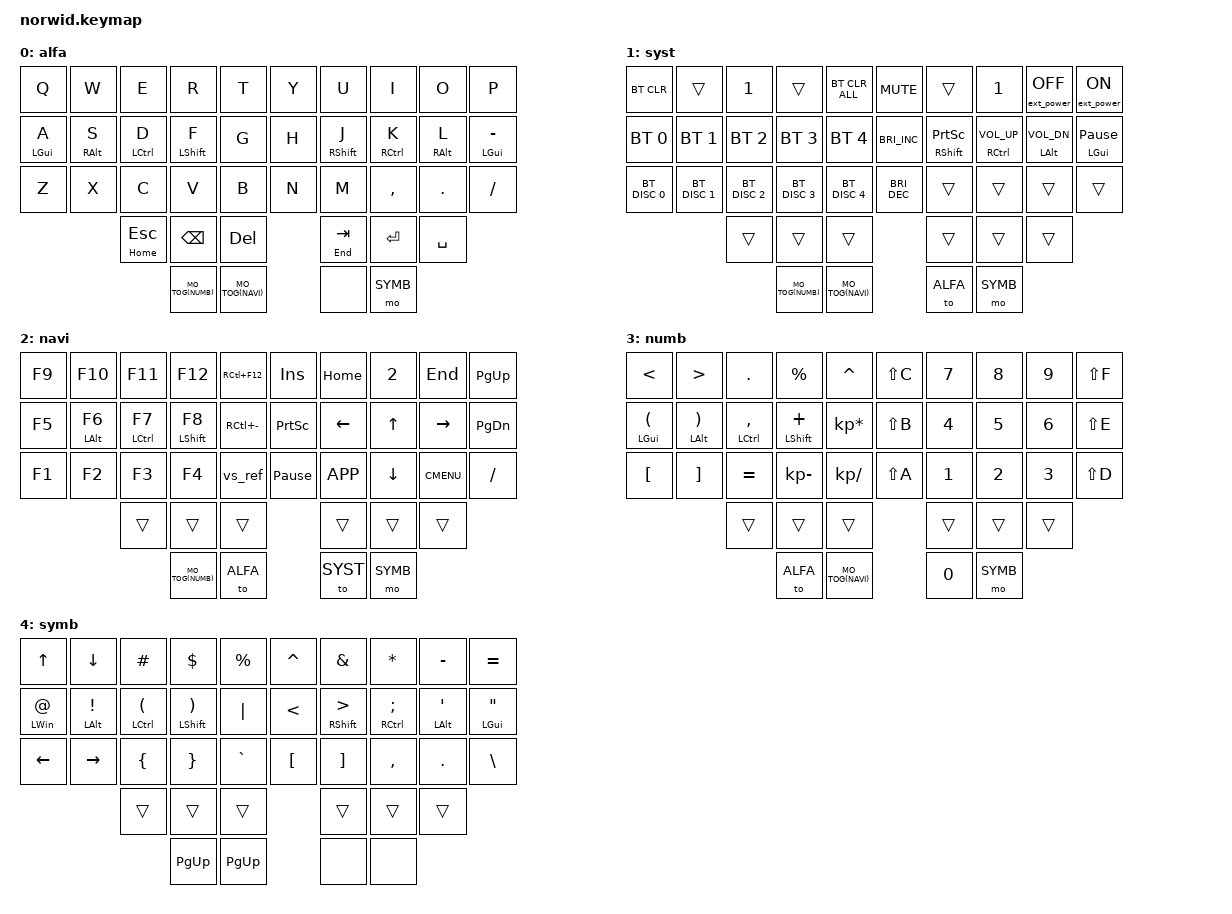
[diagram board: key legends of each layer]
#include <behaviors.dtsi>
#include <dt-bindings/zmk/keys.h>
#include <dt-bindings/zmk/bt.h>
#include <dt-bindings/zmk/outputs.h>
#include <dt-bindings/zmk/ext_power.h>

#define MO_TOG(layer) &mo_tog layer layer 
#define ALFA 0
#define SYST 1
#define NAVI 2
#define NUMB 3
#define SYMB 4


/ {
    macros {
        vs_ref: vs_ref {
            compatible = "zmk,behavior-macro";
            #binding-cells = <0>;
            bindings
                = <&macro_press &kp LCTRL>
                , <&macro_tap &kp K &kp R>
                , <&macro_release &kp LCTRL>
                ;
        };
    };
    behaviors {
        hm: homerow_mods {
            compatible = "zmk,behavior-hold-tap";
            #binding-cells = <2>;
            tapping-term-ms = <250>;
            flavor = "tap-preferred";
            bindings = <&kp>, <&kp>;
        };
        mo_tog: behavior_mo_tog {
            compatible = "zmk,behavior-hold-tap";
            #binding-cells = <2>;
            flavor = "hold-preferred";
            tapping-term-ms = <200>;
            bindings = <&mo>, <&tog>;
        };
        hml: home_row_mod_left {
            compatible = "zmk,behavior-hold-tap";
            display-name = "Home Row Mod L";
            #binding-cells = <2>;
            flavor = "balanced";
            require-prior-idle-ms = <100>;
            tapping-term-ms = <280>;
            quick-tap-ms = <175>;
            bindings = <&kp>, <&kp>;
            hold-trigger-key-positions = <5 6 7 8 9 15 16 17 18 19 25 26 27 28 29 35 36 37 38 39>;
            hold-trigger-on-release;
        };
        hmr: home_row_mod_right {
            compatible = "zmk,behavior-hold-tap";
            display-name = "Home Row Mod R";
            #binding-cells = <2>;
            flavor = "balanced";
            require-prior-idle-ms = <100>;
            tapping-term-ms = <280>;
            quick-tap-ms = <175>;
            bindings = <&kp>, <&kp>;
            hold-trigger-key-positions = <0 1 2 3 4 10 11 12 13 14 20 21 22 23 24 30 31 32 33 34>;
            hold-trigger-on-release;
        };
    };
    keymap {
        compatible = "zmk,keymap";
        alfa_layer {
            display-name = "alfa";
            bindings = <
                &kp Q       &kp W       &kp E        &kp R         &kp T       &kp Y  &kp U        &kp I        &kp O       &kp P
                &hml LGUI A &hml RALT S &hml LCTRL D &hml LSHFT F  &kp G       &kp H  &hmr RSHFT J &hmr RCTRL K &hmr RALT L &hmr LGUI MINUS
                &kp Z       &kp X       &kp C        &kp V         &kp B       &kp N  &kp M        &kp COMMA    &kp DOT     &kp FSLH     
                                        &hml HOME ESC  &kp BSPC    &kp DEL      &hmr END TAB &kp ENTER  &kp SPACE
                                                MO_TOG(NUMB)    MO_TOG(NAVI)           &none   &mo SYMB
            >;
        };
        sys_layer {
            display-name = "syst";
            bindings = <
                &bt BT_CLR    &trans        &kp N1        &trans        &bt BT_CLR_ALL          &kp C_MUTE  &trans      &kp N1      &ext_power EP_OFF      &ext_power EP_ON
                &bt BT_SEL 0  &bt BT_SEL 1  &bt BT_SEL 2  &bt BT_SEL 3  &bt BT_SEL 4            &kp C_BRI_INC &hmr RSHFT PSCRN &hmr RCTRL C_VOL_UP &hmr LALT C_VOL_DN  &hmr LGUI PAUSE_BREAK
                &bt BT_DISC 0 &bt BT_DISC 1 &bt BT_DISC 2 &bt BT_DISC 3 &bt BT_DISC 4           &kp C_BRI_DEC &trans      &trans      &trans      &trans   
                                                &trans     &trans       &trans                  &trans     &trans     &trans
                                                    MO_TOG(NUMB)     MO_TOG(NAVI)                   &to ALFA    &mo SYMB
            >;
        };
        nav_layer {
            display-name = "navi";
            bindings = <
                &kp F9  &kp F10      &kp F11        &kp F12        &kp RC(F12)                  &kp INS         &kp HOME  &kp N2    &kp END    &kp PG_UP
                &kp F5  &hml LALT F6 &hml LCTRL F7  &hml LSHFT F8  &kp RC(MINUS)                &kp PSCRN       &kp LEFT  &kp UP    &kp RIGHT  &kp PG_DN
                &kp F1  &kp F2       &kp F3         &kp F4         &vs_ref                      &kp PAUSE_BREAK &kp K_APP &kp DOWN  &kp K_CMENU  &kp FSLH     
                                                  &trans      &trans      &trans               &trans      &trans      &trans
                                                     MO_TOG(NUMB)    &to ALFA                     &to SYST    &mo SYMB
            >;
        };
        numbers_layer {
            display-name = "numb";
            bindings = <
                &kp LT            &kp GT            &kp DOT          &kp PRCNT         &kp CARET         &kp LS(C) &kp N7 &kp N8 &kp N9 &kp LS(F)
                &hml LGUI LPAR    &hml LALT RPAR    &hml LCTRL COMMA &hml LSHFT PLUS   &kp KP_MULTIPLY   &kp LS(B) &kp N4 &kp N5 &kp N6 &kp LS(E)
                &kp LBKT          &kp RBKT          &kp EQUAL           &kp KP_MINUS      &kp KP_DIVIDE     &kp LS(A) &kp N1 &kp N2 &kp N3 &kp LS(D)     
                                                                   &trans      &trans      &trans               &trans      &trans      &trans
                                                                        &to ALFA     MO_TOG(NAVI)                    &kp N0     &mo SYMB
            >;
        };
        symbol_layer {
            display-name = "symb";
            bindings = <
                &kp UP     &kp DOWN        &kp HASH       &kp DLLR       &kp PRCNT       &kp CARET &kp AMPS      &kp STAR        &kp MINUS      &kp EQUAL
                &hml LWIN AT  &hml LALT EXCL &hml LCTRL LPAR &hml LSHFT RPAR &kp PIPE    &kp LT    &hmr RSHFT GT &hmr RCTRL SEMI &hmr LALT APOS &hmr LGUI DQT
                &kp LEFT   &kp RIGHT     &kp LBRC       &kp RBRC       &kp GRAVE         &kp LBKT  &kp RBKT      &kp COMMA       &kp DOT        &kp BSLH     
                                            &trans      &trans      &trans               &trans      &trans      &trans
                                                &kp PG_UP    &kp PG_UP                         &none       &none
            >;
        };
    }; 
};
